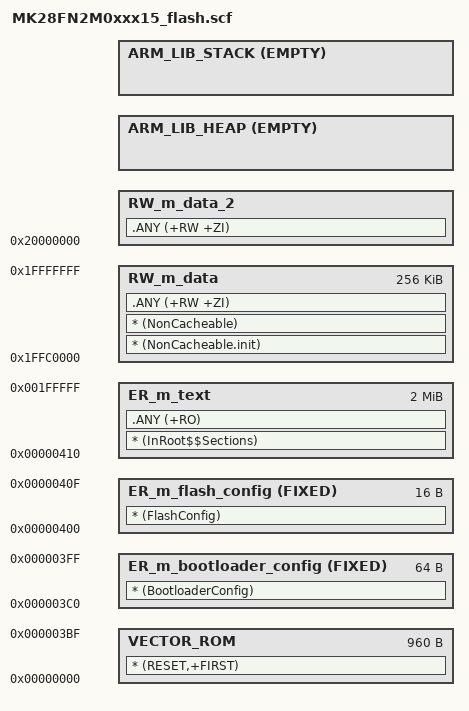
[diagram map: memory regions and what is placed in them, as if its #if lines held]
#! armcc -E
/*
** ###################################################################
**     Processors:          MK28FN2M0CAU15R
**                          MK28FN2M0VMI15
**
**     Compiler:            Keil ARM C/C++ Compiler
**     Reference manual:    K28P210M150SF5RM, Rev. 4, Aug 2017
**     Version:             rev. 1.3, 2018-01-09
**     Build:               b180801
**
**     Abstract:
**         Linker file for the Keil ARM C/C++ Compiler
**
**     Copyright 2016 Freescale Semiconductor, Inc.
**     Copyright 2016-2018 NXP
**
**     SPDX-License-Identifier: BSD-3-Clause
**
**     http:                 www.nxp.com
**     mail:                 support@nxp.com
**
** ###################################################################
*/

#define m_interrupts_start             0x00000000
#define m_interrupts_size              0x000003C0

#define m_bootloader_config_start      0x000003C0
#define m_bootloader_config_size       0x00000040

#define m_flash_config_start           0x00000400
#define m_flash_config_size            0x00000010

#define m_text_start                   0x00000410
#define m_text_size                    0x001FFBF0

#define m_data_start                   0x1FFC0000
#define m_data_size                    0x00040000

#define m_data_2_start                 0x20000000
#define m_data_2_size                  0x00040000

/* Sizes */
#if (defined(__stack_size__))
  #define Stack_Size                   __stack_size__
#else
  #define Stack_Size                   25000
#endif

#if (defined(__heap_size__))
  #define Heap_Size                    __heap_size__
#else
  #define Heap_Size                    40000
#endif

LR_m_text m_interrupts_start m_text_start+m_text_size-m_interrupts_start { ; load region size_region
  VECTOR_ROM m_interrupts_start m_interrupts_size { ; load address = execution address
    * (RESET,+FIRST)
  }
  ER_m_bootloader_config m_bootloader_config_start FIXED m_bootloader_config_size { ; load address = execution address
    * (BootloaderConfig)
  }
  ER_m_flash_config m_flash_config_start FIXED m_flash_config_size { ; load address = execution address
    * (FlashConfig)
  }
  ER_m_text m_text_start m_text_size { ; load address = execution address
    * (InRoot$$Sections)
    .ANY (+RO)
  }

  RW_m_data m_data_start m_data_size { ; RW data
    * (NonCacheable.init)
    * (NonCacheable)
    .ANY (+RW +ZI)
  }
  RW_m_data_2 m_data_2_start m_data_2_size-Stack_Size-Heap_Size { ; RW data
    .ANY (+RW +ZI)
  }
  ARM_LIB_HEAP ((ImageLimit(RW_m_data_2) == m_data_2_start) ? m_data_2_start : +0) EMPTY Heap_Size { ; Heap region growing up
  }
  ARM_LIB_STACK m_data_2_start+m_data_2_size EMPTY -Stack_Size { ; Stack region growing down
  }
}

